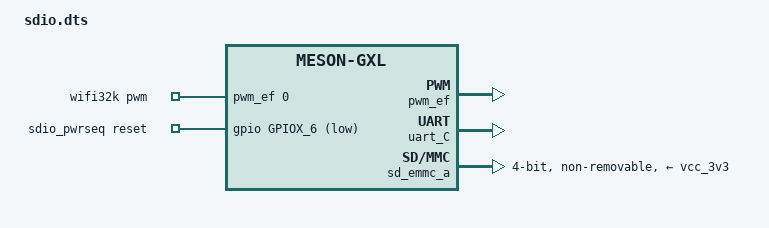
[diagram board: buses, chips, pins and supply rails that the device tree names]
// SPDX-License-Identifier: (GPL-2.0-or-later OR MIT)
/*
 * Copyright (c) 2020 BayLibre, SAS.
 * Author: Nicolas Belin <nbelin@baylibre.com>
 */
/*
 * Summary: SDIO on emmc_a. This includes enabling pwm-e (the WiFi 32k
 * clock) and uart_C with RTS/CTS (Bluetooth).
 *
 * Pins (Header.Pin  Name  Pad  Ref — cross-ref gpio.map):
 *   7J1.19   GPIOX_8       A5      UART_C_TX
 *   7J1.21   GPIOX_9       B5      UART_C_RX
 *   7J1.22   GPIOX_0       A2      WIFI_D0
 *   7J1.23   GPIOX_11      B6      UART_C_RTS_N
 *   7J1.24   GPIOX_10      A4      UART_C_CTS_N
 *   7J1.26   GPIOX_1       B3      WIFI_D1
 *   7J1.32   GPIOX_16      A3      WIFI_32K
 *   7J1.33   GPIOX_6       D2      WIFI_PWREN
 *   7J1.36   GPIOX_2       C2      WIFI_D2
 *   7J1.37   GPIOX_5       C3      WIFI_CMD
 *   7J1.38   GPIOX_3       B1      WIFI_D3
 *   7J1.40   GPIOX_4       B2      WIFI_SD_CLK
 *
 * Resource-provides: bus:uart_C
 */
/dts-v1/;
/plugin/;

#include <dt-bindings/gpio/gpio.h>
#include <dt-bindings/gpio/meson-gxl-gpio.h>

/ {
	compatible = "libre-computer,aml-s805x-ac",
		"libretech,aml-s805x-ac",
		"libre-computer,aml-s805x-ac-v2",
		"libretech,aml-s805x-ac-v2",
		"amlogic,s805x",
		"amlogic,meson-gxl";

	fragment@0 {
		target = <&pwm_ef>;

		__overlay__ {
			status = "okay";
			pinctrl-0 = <&pwm_e_pins>;
			pinctrl-names = "default";
		};
	};

	fragment@1 {
		target-path = "/aliases";

		__overlay__ {
			serial1 = "/soc/bus@c1100000/serial@8700";
		};
	};

	fragment@2 {
		target = <&uart_C>;

		__overlay__ {
			status = "okay";
			pinctrl-0 = <&uart_c_pins>, <&uart_c_cts_rts_pins>;
			pinctrl-names = "default";
			uart-has-rtscts;
		};
	};

	fragment@3 {
		target-path = "/";

		__overlay__ {
			wifi32k: wifi32k {
				compatible = "pwm-clock";
				#clock-cells = <0>;
				clock-frequency = <32768>;
				pwms = <&pwm_ef 0 30518 0>; /* PWM_E at 32.768KHz */
			};

			sdio_pwrseq: sdio-pwrseq {
				compatible = "mmc-pwrseq-simple";
				reset-gpios = <&gpio GPIOX_6 GPIO_ACTIVE_LOW>;
				clocks = <&wifi32k>;
				clock-names = "ext_clock";
			};
		};
	};

	fragment@4 {
		target = <&sd_emmc_a>;

		__overlay__ {
			status = "okay";
			pinctrl-0 = <&sdio_pins>;
			pinctrl-1 = <&sdio_clk_gate_pins>;
			pinctrl-names = "default", "clk-gate";
			#address-cells = <1>;
			#size-cells = <0>;

			bus-width = <4>;
			cap-sd-highspeed;
			max-frequency = <50000000>;

			non-removable;
			disable-wp;

			mmc-pwrseq = <&sdio_pwrseq>;

			vmmc-supply = <&vcc_3v3>;
			vqmmc-supply = <&vcc_3v3>;
		};
	};
};
